# ADSP-SC83xW_HPC register map
Vendor: Analog Devices; Series: ADSP-SC83xW_HPC; File version: 3.0.3.517
CPU: 
Registers are 32-bit, read-write, reset 0x0 unless marked. A register's access mark holds for its fields unless they carry their own. Offsets are from the block's base; [hi:lo] are bit positions; {n}, {i} and the like mark numbered series.

## ASRC0 — Sample Rate Converter Module
Base 0x310C9000
Same registers: ASRC1 0x310CA000
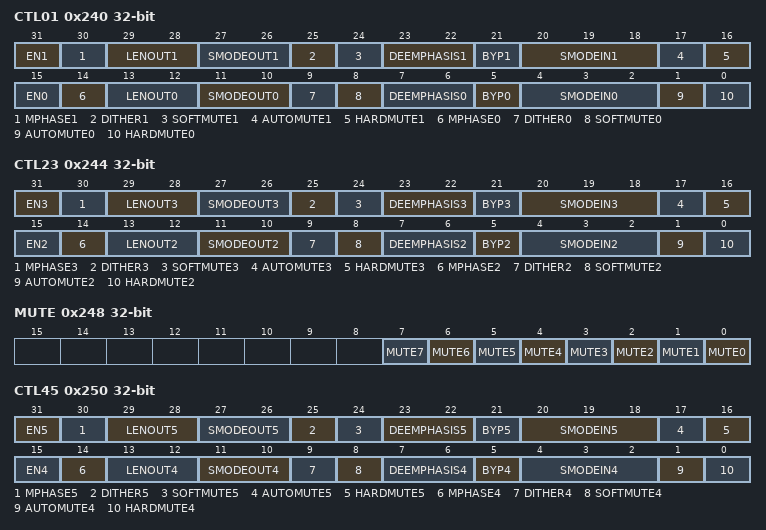
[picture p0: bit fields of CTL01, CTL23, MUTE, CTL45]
0x240 CTL01 — Control Register for ASRC 0 and 1
  [31] EN1 range 0x00000000..0x00000001 — Enable SRC 1
  [30] MPHASE1 — Matched-phase Mode 1
  [29:28] LENOUT1 — Length Output 1
  [27:26] SMODEOUT1 — Serial Mode Output 1
  [25] DITHER1 — Dither Enable 1
  [24] SOFTMUTE1
  [23:22] DEEMPHASIS1 — De-emphasize Audio 1
  [21] BYP1 range 0x00000000..0x00000001 — Bypass 1
  [20:18] SMODEIN1 — Serial Mode Input 1
  [17] AUTOMUTE1 — Auto Hard Mute 1
  [16] HARDMUTE1
  [15] EN0 range 0x00000000..0x00000001 — Enable SRC 0
  [14] MPHASE0 — Matched-phase Mode 0
  [13:12] LENOUT0 — Length Output 0
  [11:10] SMODEOUT0 — Serial Mode Output 0
  [9] DITHER0 — Dither Enable 0
  [8] SOFTMUTE0
  [7:6] DEEMPHASIS0 — De-emphasize Audio 0
  [5] BYP0 range 0x00000000..0x00000001 — Bypass 0
  [4:2] SMODEIN0 — Serial Mode Input 0
  [1] AUTOMUTE0 — Auto Hard Mute 0
  [0] HARDMUTE0
0x244 CTL23 — Control Register for ASRC 2 and 3
  [31] EN3 range 0x00000000..0x00000001 — Enable SRC 3
  [30] MPHASE3 — Matched-phase Mode 3
  [29:28] LENOUT3 — Length Output 3
  [27:26] SMODEOUT3 — Serial Mode Output 3
  [25] DITHER3 — Dither Enable 3
  [24] SOFTMUTE3
  [23:22] DEEMPHASIS3 — De-emphasize Audio 3
  [21] BYP3 range 0x00000000..0x00000001 — Bypass 3
  [20:18] SMODEIN3 — Serial Mode Input 3
  [17] AUTOMUTE3 — Auto Hard Mute 3
  [16] HARDMUTE3
  [15] EN2 range 0x00000000..0x00000001 — Enable SRC 2
  [14] MPHASE2 — Matched-phase Mode 2
  [13:12] LENOUT2 — Length Output 2
  [11:10] SMODEOUT2 — Serial Mode Output 2
  [9] DITHER2 — Dither Enable 2
  [8] SOFTMUTE2
  [7:6] DEEMPHASIS2 — De-emphasize Audio 2
  [5] BYP2 range 0x00000000..0x00000001 — Bypass 2
  [4:2] SMODEIN2 — Serial Mode Input 2
  [1] AUTOMUTE2 — Auto Hard Mute 2
  [0] HARDMUTE2
0x248 MUTE
  [n] MUTE{n} range 0x00000000..0x00000001 (n=0..7) — Mute ASRC{n}
0x250 CTL45 — Control Register For ASRC 4 And 5
  [31] EN5 range 0x00000000..0x00000001 — Enable SRC 5
  [30] MPHASE5 — Matched-phase Mode 5
  [29:28] LENOUT5 — Length Output 5
  [27:26] SMODEOUT5 — Serial Mode Output 5
  [25] DITHER5 — Dither Enable 5
  [24] SOFTMUTE5
  [23:22] DEEMPHASIS5 — De-emphasize Audio 5
  [21] BYP5 range 0x00000000..0x00000001 — Bypass 5
  [20:18] SMODEIN5 — Serial Mode Input 5
  [17] AUTOMUTE5 — Auto Hard Mute 5
  [16] HARDMUTE5
  [15] EN4 range 0x00000000..0x00000001 — Enable SRC 4
  [14] MPHASE4 — Matched-phase Mode 4
  [13:12] LENOUT4 — Length Output 4
  [11:10] SMODEOUT4 — Serial Mode Output 4
  [9] DITHER4 — Dither Enable 4
  [8] SOFTMUTE4
  [7:6] DEEMPHASIS4 — De-emphasize Audio 4
  [5] BYP4 range 0x00000000..0x00000001 — Bypass 4
  [4:2] SMODEIN4 — Serial Mode Input 4
  [1] AUTOMUTE4 — Auto Hard Mute 4
  [0] HARDMUTE4
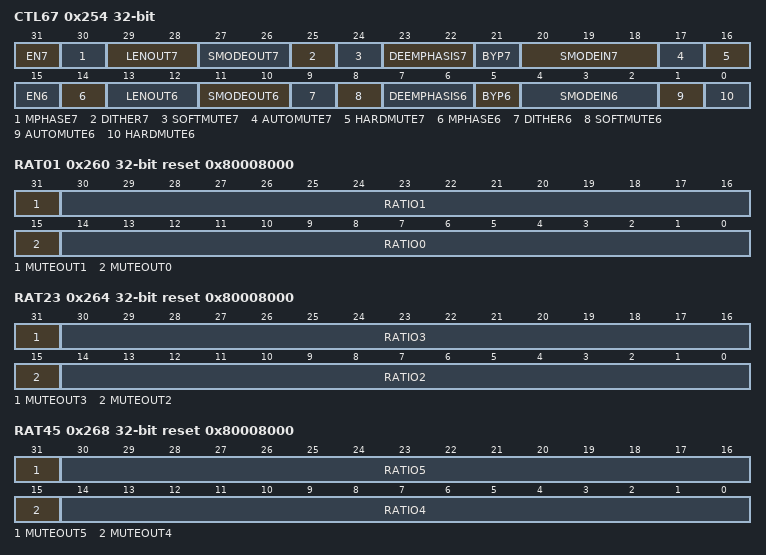
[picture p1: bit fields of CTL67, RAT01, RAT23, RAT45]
0x254 CTL67 — Control Register for ASRC 6 and 7
  [31] EN7 range 0x00000000..0x00000001 — Enable SRC 7
  [30] MPHASE7 — Matched-phase Mode 7
  [29:28] LENOUT7 — Length Output 7
  [27:26] SMODEOUT7 — Serial Mode Output 7
  [25] DITHER7 — Dither Enable 7
  [24] SOFTMUTE7
  [23:22] DEEMPHASIS7 — De-emphasize Audio 7
  [21] BYP7 range 0x00000000..0x00000001 — Bypass 7
  [20:18] SMODEIN7 — Serial Mode Input 7
  [17] AUTOMUTE7 — Auto Hard Mute 7
  [16] HARDMUTE7
  [15] EN6 range 0x00000000..0x00000001 — Enable SRC 6
  [14] MPHASE6 — Matched-phase Mode 6
  [13:12] LENOUT6 — Length Output 6
  [11:10] SMODEOUT6 — Serial Mode Output 6
  [9] DITHER6 — Dither Enable 6
  [8] SOFTMUTE6
  [7:6] DEEMPHASIS6 — De-emphasize Audio 6
  [5] BYP6 range 0x00000000..0x00000001 — Bypass 6
  [4:2] SMODEIN6 — Serial Mode Input 6
  [1] AUTOMUTE6 — Auto Hard Mute 6
  [0] HARDMUTE6
0x260 RAT01 reset 0x80008000 — Ratio Register for ASRC 0 and 1
  [31] MUTEOUT1 ro — Mute Status for ASRC1
  [30:16] RATIO1 ro — Sampling Ratio of Frame Syncs for ASRC1
  [15] MUTEOUT0 ro — Mute Status for ASRC0
  [14:0] RATIO0 ro — Sampling Ratio of Frame Syncs for ASRC0
0x264 RAT23 reset 0x80008000 — Ratio Register for ASRC 2 and 3
  [31] MUTEOUT3 ro — Mute Status for ASRC3
  [30:16] RATIO3 ro — Sampling Ratio of Frame Syncs for ASRC3
  [15] MUTEOUT2 ro — Mute Status for ASRC2
  [14:0] RATIO2 ro — Sampling Ratio of Frame Syncs for ASRC2
0x268 RAT45 reset 0x80008000 — Ratio Register For ASRC 4 and 5
  [31] MUTEOUT5 ro — Mute Status for ASRC5
  [30:16] RATIO5 ro — Sampling Ratio of Frame Syncs for ASRC5
  [15] MUTEOUT4 ro — Mute Status for ASRC4
  [14:0] RATIO4 ro — Sampling Ratio of Frame Syncs for ASRC4
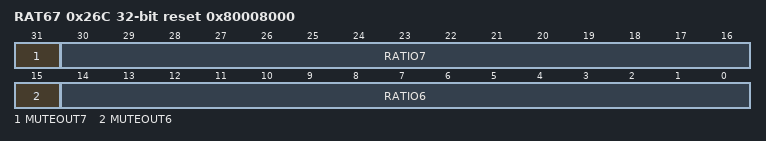
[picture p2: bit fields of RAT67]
0x26C RAT67 reset 0x80008000 — Ratio Register for ASRC 6 and 7
  [31] MUTEOUT7 ro — Mute Status for ASRC7
  [30:16] RATIO7 ro — Sampling Ratio of Frame Syncs for ASRC7
  [15] MUTEOUT6 ro — Mute Status for ASRC6
  [14:0] RATIO6 ro — Sampling Ratio of Frame Syncs for ASRC6
